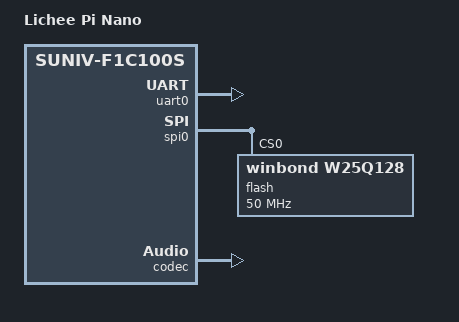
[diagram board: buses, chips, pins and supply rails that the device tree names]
// SPDX-License-Identifier: (GPL-2.0+ OR X11)
/*
 * Copyright 2018 Icenowy Zheng <icenowy@aosc.io>
 */

/dts-v1/;
#include "suniv-f1c100s.dtsi"

/ {
	model = "Lichee Pi Nano";
	compatible = "licheepi,licheepi-nano", "allwinner,suniv-f1c100s";

	aliases {
		serial0 = &uart0;
	};

	chosen {
		stdout-path = "serial0:115200n8";
	};
};

&uart0 {
	pinctrl-names = "default";
	pinctrl-0 = <&uart0_pe_pins>;
	status = "okay";
};

&spi0 {
	pinctrl-names = "default";
	pinctrl-0 = <&spi0_pc_pins>;
	status = "okay";
	flash@0 {
		#address-cells = <1>;
		#size-cells = <1>;
		compatible = "winbond,w25q128", "jedec,spi-nor";
		reg = <0>;
		spi-max-frequency = <50000000>;
	};
};

&codec {
	allwinner,audio-routing =
		"Headphone", "HP",
		"Headphone", "HPCOM",
		"MIC", "Mic";
	status = "okay";
};
